AUTOSAR XML (schema 4-2-2)
package /EB/SoftwareComponents
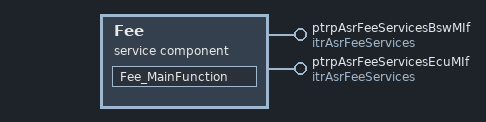
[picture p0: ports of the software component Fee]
  service sw component type Fee: category=ASR_Interfaces
    provide port ptrpAsrFeeServicesBswMIf: provided-interface=itrAsrFeeServices
    provide port ptrpAsrFeeServicesEcuMIf: provided-interface=itrAsrFeeServices
    behavior Fee_IB: handle-termination-and-restart=NO-SUPPORT
      runnable Fee_MainFunction
package /EB/TriggerInterfaces
  trigger interface itrAsrFeeServices
    trigger Fee_Init: trigger-period={cse-code=1000, cse-code-factor=0}
    trigger Fee_MainFunction: trigger-period={cse-code=1000, cse-code-factor=0}
